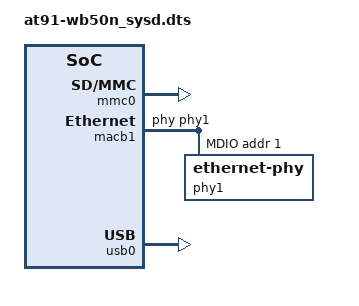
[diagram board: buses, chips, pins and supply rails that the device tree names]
// SPDX-License-Identifier: GPL-2.0
/*
 * at91-wb50n_sysd.dts - Device Tree file for wb50n evaluation board
 *
 *  Copyright (C) 2018 Laird Connectivity
 *
 */

/dts-v1/;

#include "at91-wb50n_sysd.dtsi"

&mmc0 {
	status = "okay";
};

&macb1 {
	status = "okay";

	phy-handle = <&phy1>;

	mdio {
		#address-cells = <1>;
		#size-cells = <0>;

		phy1: ethernet-phy@1 {
			reg = <1>;
		};
	};
};

&usb0 {
	status = "okay";
};
